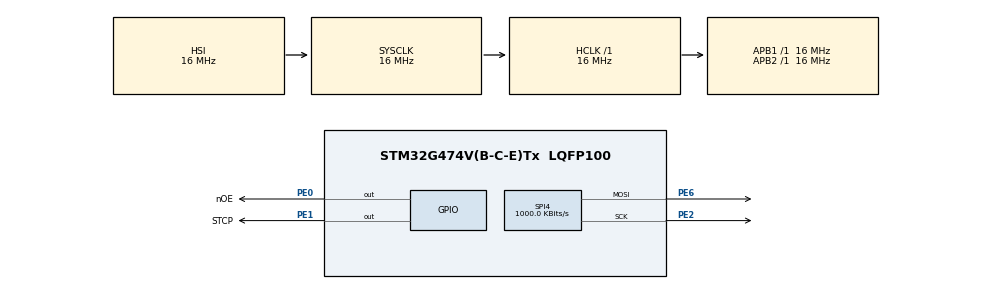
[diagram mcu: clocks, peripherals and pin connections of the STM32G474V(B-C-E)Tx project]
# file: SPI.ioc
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Mcu.Family=STM32G4
Mcu.Name=STM32G474V(B-C-E)Tx
Mcu.Package=LQFP100
NVIC.PriorityGroup=NVIC_PRIORITYGROUP_4
PE0.GPIO_Label=nOE
PE0.Signal=GPIO_Output
PE1.GPIO_Label=STCP
PE1.Signal=GPIO_Output
PE2.Mode=TX_Only_Simplex_Unidirect_Master
PE2.Signal=SPI4_SCK
PE6.Mode=TX_Only_Simplex_Unidirect_Master
PE6.Signal=SPI4_MOSI
ProjectManager.HeapSize=0x200
ProjectManager.StackSize=0x400
ProjectManager.TargetToolchain=STM32CubeIDE
RCC.AHBFreq_Value=16000000
RCC.APB1Freq_Value=16000000
RCC.APB1TimFreq_Value=16000000
RCC.APB2Freq_Value=16000000
RCC.APB2TimFreq_Value=16000000
RCC.CortexFreq_Value=16000000
RCC.EXTERNAL_CLOCK_VALUE=12288000
RCC.HCLKFreq_Value=16000000
RCC.HSE_VALUE=8000000
RCC.HSI48_VALUE=48000000
RCC.HSI_VALUE=16000000
RCC.LSE_VALUE=32768
RCC.SYSCLKFreq_VALUE=16000000
RCC.USBFreq_Value=64000000
RCC.VCOOutputFreq_Value=128000000
SPI4.BaudRatePrescaler=SPI_BAUDRATEPRESCALER_16
SPI4.CalculateBaudRate=1000.0 KBits/s
SPI4.DataSize=SPI_DATASIZE_8BIT
SPI4.Direction=SPI_DIRECTION_2LINES
SPI4.Mode=SPI_MODE_MASTER
SPI4.VirtualType=VM_MASTER
VP_SYS_VS_DBSignals.Mode=DisableDeadBatterySignals
board=custom

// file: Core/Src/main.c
/* USER CODE BEGIN Header */
/**
  ******************************************************************************
  * @file           : main.c
  * @brief          : Main program body
  ******************************************************************************
  * @attention
  *
  * Copyright (c) 2025 STMicroelectronics.
  * All rights reserved.
  *
  * This software is licensed under terms that can be found in the LICENSE file
  * in the root directory of this software component.
  * If no LICENSE file comes with this software, it is provided AS-IS.
  *
  ******************************************************************************
  */
/* USER CODE END Header */
#include "main.h"

SPI_HandleTypeDef hspi4;

void SystemClock_Config(void);
static void MX_GPIO_Init(void);
static void MX_SPI4_Init(void);

/* USER CODE BEGIN 0 */
void hc595_send(uint8_t data){
//	for(int i =0 ; i<8;++i){
//		HAL_GPIO_WritePin(DS_GPIO_Port, DS_Pin, data & (1 << 7)? GPIO_PIN_SET : GPIO_PIN_RESET);
//		HAL_GPIO_WritePin(SHCP_GPIO_Port, SHCP_Pin, GPIO_PIN_SET);
//		HAL_GPIO_WritePin(SHCP_GPIO_Port, SHCP_Pin, GPIO_PIN_RESET);
//		data <<= 1;
//	}
	HAL_SPI_Transmit(&hspi4, &data, 1, 10);
	HAL_GPIO_WritePin(STCP_GPIO_Port, STCP_Pin, GPIO_PIN_SET);
	HAL_GPIO_WritePin(STCP_GPIO_Port, STCP_Pin, GPIO_PIN_RESET);
}

/* USER CODE END 0 */

int main(void)
{

  /* MCU Configuration--------------------------------------------------------*/

  /* Reset of all peripherals, Initializes the Flash interface and the Systick. */
  HAL_Init();

  /* Configure the system clock */
  SystemClock_Config();

  /* Initialize all configured peripherals */
  MX_GPIO_Init();
  MX_SPI4_Init();
  /* USER CODE BEGIN 2 */
  uint8_t flow = 1;
  /* USER CODE END 2 */

  /* Infinite loop */
  while (1)
  {

    /* USER CODE BEGIN 3 */
  	hc595_send(flow);
  	flow<<=1;
  	if(flow == 0)flow=1;
  	HAL_Delay(499);

  }
  /* USER CODE END 3 */
}

void SystemClock_Config(void)
{
  RCC_OscInitTypeDef RCC_OscInitStruct = {0};
  RCC_ClkInitTypeDef RCC_ClkInitStruct = {0};

  /** Configure the main internal regulator output voltage
  */
  HAL_PWREx_ControlVoltageScaling(PWR_REGULATOR_VOLTAGE_SCALE1);

  /** Initializes the RCC Oscillators according to the specified parameters
  * in the RCC_OscInitTypeDef structure.
  */
  RCC_OscInitStruct.OscillatorType = RCC_OSCILLATORTYPE_HSI;
  RCC_OscInitStruct.HSIState = RCC_HSI_ON;
  RCC_OscInitStruct.HSICalibrationValue = RCC_HSICALIBRATION_DEFAULT;
  RCC_OscInitStruct.PLL.PLLState = RCC_PLL_NONE;
  if (HAL_RCC_OscConfig(&RCC_OscInitStruct) != HAL_OK)
  {
    Error_Handler();
  }

  /** Initializes the CPU, AHB and APB buses clocks
  */
  RCC_ClkInitStruct.ClockType = RCC_CLOCKTYPE_HCLK|RCC_CLOCKTYPE_SYSCLK
                              |RCC_CLOCKTYPE_PCLK1|RCC_CLOCKTYPE_PCLK2;
  RCC_ClkInitStruct.SYSCLKSource = RCC_SYSCLKSOURCE_HSI;
  RCC_ClkInitStruct.AHBCLKDivider = RCC_SYSCLK_DIV1;
  RCC_ClkInitStruct.APB1CLKDivider = RCC_HCLK_DIV1;
  RCC_ClkInitStruct.APB2CLKDivider = RCC_HCLK_DIV1;

  if (HAL_RCC_ClockConfig(&RCC_ClkInitStruct, FLASH_LATENCY_0) != HAL_OK)
  {
    Error_Handler();
  }
}

static void MX_SPI4_Init(void)
{

  /* SPI4 parameter configuration*/
  hspi4.Instance = SPI4;
  hspi4.Init.Mode = SPI_MODE_MASTER;
  hspi4.Init.Direction = SPI_DIRECTION_2LINES;
  hspi4.Init.DataSize = SPI_DATASIZE_8BIT;
  hspi4.Init.CLKPolarity = SPI_POLARITY_LOW;
  hspi4.Init.CLKPhase = SPI_PHASE_1EDGE;
  hspi4.Init.NSS = SPI_NSS_SOFT;
  hspi4.Init.BaudRatePrescaler = SPI_BAUDRATEPRESCALER_16;
  hspi4.Init.FirstBit = SPI_FIRSTBIT_MSB;
  hspi4.Init.TIMode = SPI_TIMODE_DISABLE;
  hspi4.Init.CRCCalculation = SPI_CRCCALCULATION_DISABLE;
  hspi4.Init.CRCPolynomial = 7;
  hspi4.Init.CRCLength = SPI_CRC_LENGTH_DATASIZE;
  hspi4.Init.NSSPMode = SPI_NSS_PULSE_ENABLE;
  if (HAL_SPI_Init(&hspi4) != HAL_OK)
  {
    Error_Handler();
  }

}

static void MX_GPIO_Init(void)
{
  GPIO_InitTypeDef GPIO_InitStruct = {0};

  /* GPIO Ports Clock Enable */
  __HAL_RCC_GPIOE_CLK_ENABLE();

  /*Configure GPIO pin Output Level */
  HAL_GPIO_WritePin(GPIOE, nOE_Pin|STCP_Pin, GPIO_PIN_RESET);

  /*Configure GPIO pins : nOE_Pin STCP_Pin */
  GPIO_InitStruct.Pin = nOE_Pin|STCP_Pin;
  GPIO_InitStruct.Mode = GPIO_MODE_OUTPUT_PP;
  GPIO_InitStruct.Pull = GPIO_NOPULL;
  GPIO_InitStruct.Speed = GPIO_SPEED_FREQ_LOW;
  HAL_GPIO_Init(GPIOE, &GPIO_InitStruct);

}

void Error_Handler(void)
{
  __disable_irq();
  while (1)
  {
  }
}
